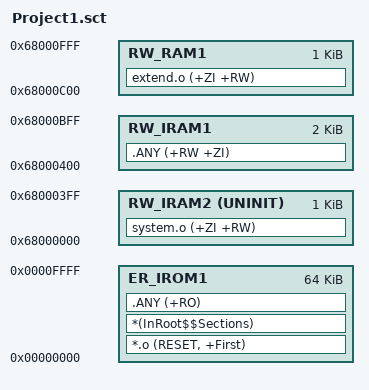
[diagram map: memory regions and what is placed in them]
; *************************************************************
; *** Scatter-Loading Description File generated by uVision ***
; *************************************************************

LR_IROM1 0x00000000 0x00010000  {    ; load region size_region
  ER_IROM1 0x00000000 0x00010000  {  ; load address = execution address
   *.o (RESET, +First)
   *(InRoot$$Sections)
   .ANY (+RO)
  }
  RW_IRAM1 0x68000400 0x00000800  {  ; RW data
   .ANY (+RW +ZI)
  }
  RW_RAM1 0x68000C00 0x00000400  {
    extend.o (+ZI +RW)
  }
  RW_IRAM2 0x68000000 UNINIT 0x00000400  {
    system.o (+ZI +RW)
  }
}

